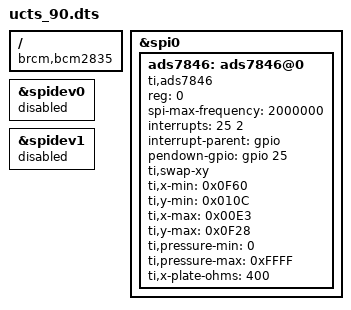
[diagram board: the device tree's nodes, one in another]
/*
 * Generic Device Tree overlay for the ADS7846 touch controller
 *
 */

/dts-v1/;
/plugin/;

/ {
	compatible = "brcm,bcm2835\0brcm,bcm2708\0brcm,bcm2709";

	fragment@0 {
		target = <&spi0>;
		__overlay__ {
			status = "okay";
		};
	};

	fragment@1 {
		target = <&spidev0>;
		__overlay__ {
			status = "disabled";
		};
	};

	fragment@2 {
		target = <&spidev1>;
		__overlay__ {
			status = "disabled";
		};
	};

	fragment@3 {
		target = <&spi0>;
		__overlay__ {
			/* needed to avoid dtc warning */
			#address-cells = <1>;
			#size-cells = <0>;

			ads7846: ads7846@0 {
				compatible = "ti,ads7846";
				reg = <0>;
				spi-max-frequency = <2000000>;
				interrupts = <25 2>; /* high-to-low edge triggered */
				interrupt-parent = <&gpio>;
				pendown-gpio = <&gpio 25 0>;
				ti,swap-xy;
				/* driver defaults */
				ti,x-min = /bits/ 16 <0x0F60>;
				ti,y-min = /bits/ 16 <0x010C>;
				ti,x-max = /bits/ 16 <0x00E3>;
				ti,y-max = /bits/ 16 <0x0F28>;
				ti,pressure-min = /bits/ 16 <0>;
				ti,pressure-max = /bits/ 16 <0xFFFF>;
				ti,x-plate-ohms = /bits/ 16 <400>;
			};
		};
	};
	
	__overrides__  {
		xmin =   <&ads7846>,"ti,x-min;0";
		ymin =   <&ads7846>,"ti,y-min;0";
		xmax =   <&ads7846>,"ti,x-max;0";
		ymax =   <&ads7846>,"ti,y-max;0";
	};
};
